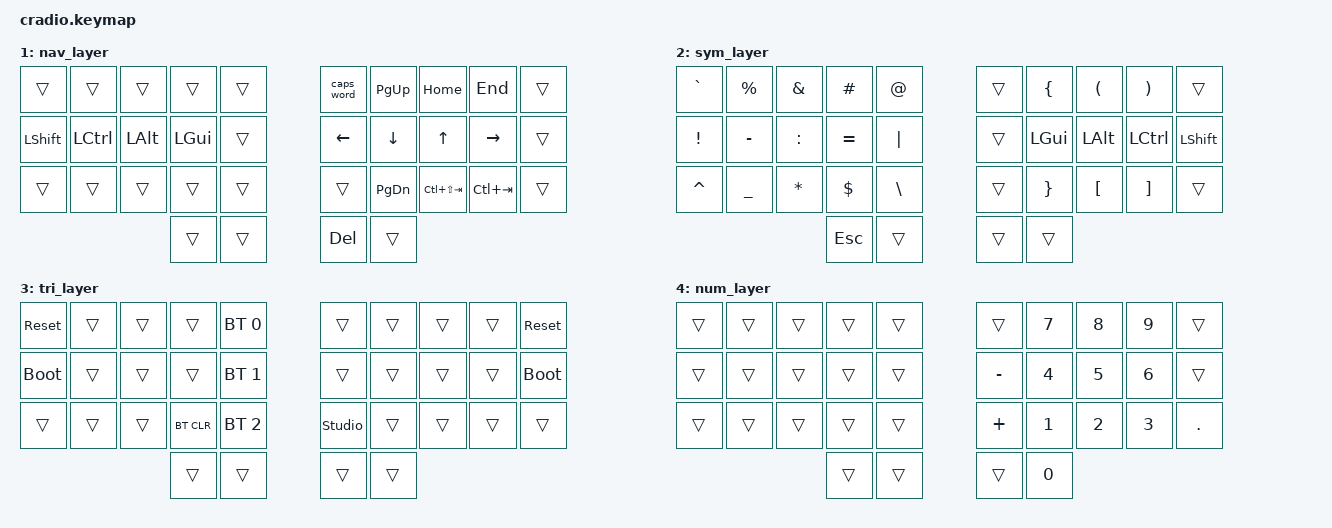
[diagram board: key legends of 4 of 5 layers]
// Copyright (c) 2022 The ZMK Contributors
// SPDX-License-Identifier: MIT

#include <behaviors.dtsi>
#include <dt-bindings/zmk/keys.h>
#include <dt-bindings/zmk/bt.h>

// Home row mods macro
#define HRML(k1,k2,k3,k4) &ht LSHFT k1  &ht LCTRL k2  &ht LALT k3  &ht LGUI k4
#define HRMR(k1,k2,k3,k4) &ht RGUI k1  &ht RALT k2  &ht RCTRL k3  &ht RSHFT k4

/ {
    behaviors {
        ht: hold_tap {
            compatible = "zmk,behavior-hold-tap";
            #binding-cells = <2>;
            flavor = "tap-preferred";
            tapping-term-ms = <220>;
            quick-tap-ms = <150>;
            require-prior-idle-ms = <100>;
            bindings = <&kp>, <&kp>;
        };
    };

    conditional_layers {
        compatible = "zmk,conditional-layers";
        tri_layer {
            if-layers = <1 2>;
            then-layer = <3>;
        };
    };

    keymap {
        compatible = "zmk,keymap";
        default_layer {
            bindings = <
        //╭──────────┬──────────┬──────────┬──────────┬──────────╮   ╭──────────┬──────────┬──────────┬──────────┬──────────╮
        //│  B       │  L       │  D       │  W       │  Z       │   │  ' "     │  F       │  O       │  U       │  J       │
            &kp B      &kp L      &kp D      &kp W      &kp Z          &kp SQT      &kp F      &kp O      &kp U      &kp J
        //├──────────┼──────────┼──────────┼──────────┼──────────┤   ├──────────┼──────────┼──────────┼──────────┼──────────┤
        //│  N       │  R       │  T       │  S       │  G       │   │  Y       │  H       │  A       │  E       │  I       │
            HRML(N,        R,         T,         S)     &kp G          &kp Y      HRMR(H,        A,         E,        I)
        //├──────────┼──────────┼──────────┼──────────┼──────────┤   ├──────────┼──────────┼──────────┼──────────┼──────────┤
        //│  Q       │  X       │  M       │  C       │  V       │   │  K       │  P       │ , <      │ . >      │ / ?      │
            &kp Q      &kp X      &kp M      &kp C      &kp V          &kp K      &kp P      &kp COMMA  &kp DOT    &kp FSLH
        //╰──────────┴──────────┴──────────┼──────────┼──────────┤   ├──────────┼──────────┼──────────┴──────────┴──────────╯
                                            &lt 1 TAB  &lt 4 ENTER    &kp BSPC  &lt 2 SPACE
        //                                 ╰──────────┴──────────╯   ╰──────────┴──────────╯
            >;
        };

        nav_layer {
            bindings = <
        //╭──────────┬──────────┬──────────┬──────────┬──────────╮   ╭──────────┬──────────┬──────────┬──────────┬──────────╮
        //│          │          │          │          │          │   │  CAPS    │ PAGE UP  │  HOME    │ END      │          │
            &trans    &trans     &trans     &trans     &trans         &caps_word &kp PG_UP   &kp HOME  &kp END    &trans
        //├──────────┼──────────┼──────────┼──────────┼──────────┤   ├──────────┼──────────┼──────────┼──────────┼──────────┤
        //│  shift   │  ctrl    │  alt     │  gui     │          │   │ LEFT     │ DOWN     │ UP       │ RIGHT    │          │
            &kp LSHFT  &kp LCTRL   &kp LALT  &kp LGUI    &trans         &kp LEFT   &kp DOWN   &kp UP   &kp RIGHT   &trans
        //├──────────┼──────────┼──────────┼──────────┼──────────┤   ├──────────┼──────────┼──────────┼──────────┼──────────┤
        //│          │          │          │          │          │   │          │ PAGE DN  │   tab L  │  tab R   │          │
             &trans    &trans     &trans     &trans     &trans         &trans     &kp PG_DN  &kp LC(LS(TAB))  &kp LC(TAB)   &trans
        //╰──────────┴──────────┴──────────┼──────────┼──────────┤   ├──────────┼──────────┼──────────┴──────────┴──────────╯
                                             &trans     &trans         &kp DEL     &trans
        //                                 ╰──────────┴──────────╯   ╰──────────┴──────────╯
            >;
        };

        sym_layer {
            bindings = <
        //╭──────────┬──────────┬──────────┬──────────┬──────────╮   ╭──────────┬──────────┬──────────┬──────────┬──────────╮
        //│  `       │  %       │  &       │  #       │  @       │   │          │  {       │  (       │  )       │          │
            &kp GRAVE   &kp PRCNT  &kp AMPS   &kp HASH   &kp AT        &trans    &kp LBRC   &kp LPAR   &kp RPAR   &trans
        //├──────────┼──────────┼──────────┼──────────┼──────────┤   ├──────────┼──────────┼──────────┼──────────┼──────────┤
        //│  !       │  -       │  :       │  =       │  |       │   │          │  gui     │  alt     │  ctrl    │  shift   │
            &kp EXCL   &kp MINUS   &kp COLON  &kp EQUAL  &kp PIPE      &trans    &kp LGUI    &kp LALT   &kp LCTRL  &kp LSHFT
        //├──────────┼──────────┼──────────┼──────────┼──────────┤   ├──────────┼──────────┼──────────┼──────────┼──────────┤
        //│   ^      │  _       │  *       │  $       │  \       │   │          │  }       │  [       │  ]       │          │
            &kp CARET   &kp UNDER  &kp ASTRK  &kp DLLR   &kp BSLH         &trans    &kp RBRC  &kp LBKT   &kp RBKT   &trans
        //╰──────────┴──────────┴──────────┼──────────┼──────────┤   ├──────────┼──────────┼──────────┴──────────┴──────────╯
                                             &kp ESC     &trans         &trans     &trans
        //                                 ╰──────────┴──────────╯   ╰──────────┴──────────╯
            >;
        };

        tri_layer {
            bindings = <
        //╭──────────┬──────────┬──────────┬──────────┬──────────╮   ╭──────────┬──────────┬──────────┬──────────┬──────────╮
        //│ RESET    │          │          │          │PROFILE 0 │   │          │          │          │          │  RESET   │
           &sys_reset  &trans     &trans     &trans    &bt BT_SEL 0    &trans     &trans     &trans     &trans    &sys_reset
        //├──────────┼──────────┼──────────┼──────────┼──────────┤   ├──────────┼──────────┼──────────┼──────────┼──────────┤
        //│BOOTLOADER│          │          │          │PROFILE 1 │   │          │          │          │          │BOOTLOADER│
          &bootloader  &trans     &trans     &trans    &bt BT_SEL 1    &trans     &trans     &trans     &trans    &bootloader
        //├──────────┼──────────┼──────────┼──────────┼──────────┤   ├──────────┼──────────┼──────────┼──────────┼──────────┤
        //│          │          │          │ CLEAR BT │PROFILE 2 │   │          │          │          │          │          │
            &trans     &trans     &trans    &bt BT_CLR &bt BT_SEL 2    &studio_unlock     &trans     &trans     &trans     &trans
        //╰──────────┴──────────┴──────────┼──────────┼──────────┤   ├──────────┼──────────┼──────────┴──────────┴──────────╯
                                             &trans     &trans         &trans     &trans
        //                                 ╰──────────┴──────────╯   ╰──────────┴──────────╯
            >;
        };
            
        num_layer {
            bindings = <
        //╭──────────┬──────────┬──────────┬──────────┬──────────╮   ╭──────────┬──────────┬──────────┬──────────┬──────────╮
        //│          │          │          │          │          |   │          │    7     │    8     │    9     │          │
            &trans      &trans     &trans     &trans     &trans         &trans     &kp N7     &kp N8     &kp N9    &trans
        //├──────────┼──────────┼──────────┼──────────┼──────────┤   ├──────────┼──────────┼──────────┼──────────┼──────────┤
        //│          │          │          │          │          │   │   -      │    4     │    5     │    6     │          │
            &trans      &trans     &trans     &trans    &trans         &kp MINUS    &kp N4     &kp N5     &kp N6    &trans
        //├──────────┼──────────┼──────────┼──────────┼──────────┤   ├──────────┼──────────┼──────────┼──────────┼──────────┤
        //│          │          │          │          │          │   │   +      │    1     │    2     │    3     │  .       │
            &trans     &trans     &trans      &trans     &trans        &kp PLUS   &kp N1     &kp N2     &kp N3     &kp DOT
        //╰──────────┴──────────┴──────────┼──────────┼──────────┤   ├──────────┼──────────┼──────────┴──────────┴──────────╯
                                             &trans     &trans         &trans     &kp N0
        //                                 ╰──────────┴──────────╯   ╰──────────┴──────────╯
            >;
        };
    };
};
